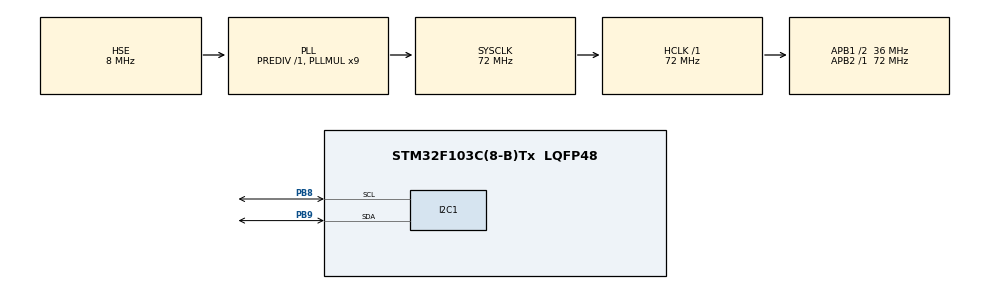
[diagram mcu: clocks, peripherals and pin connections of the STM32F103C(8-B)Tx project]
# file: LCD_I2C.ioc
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Mcu.Family=STM32F1
Mcu.Name=STM32F103C(8-B)Tx
Mcu.Package=LQFP48
NVIC.PriorityGroup=NVIC_PRIORITYGROUP_4
PA13.Mode=Serial_Wire
PA13.Signal=SYS_JTMS-SWDIO
PA14.Mode=Serial_Wire
PA14.Signal=SYS_JTCK-SWCLK
PB8.Mode=I2C
PB8.Signal=I2C1_SCL
PB9.Mode=I2C
PB9.Signal=I2C1_SDA
PD0-OSC_IN.Mode=HSE-External-Oscillator
PD0-OSC_IN.Signal=RCC_OSC_IN
PD1-OSC_OUT.Mode=HSE-External-Oscillator
PD1-OSC_OUT.Signal=RCC_OSC_OUT
ProjectManager.HeapSize=0x200
ProjectManager.StackSize=0x400
ProjectManager.TargetToolchain=STM32CubeIDE
RCC.AHBFreq_Value=72000000
RCC.APB1CLKDivider=RCC_HCLK_DIV2
RCC.APB1Freq_Value=36000000
RCC.APB1TimFreq_Value=72000000
RCC.APB2Freq_Value=72000000
RCC.APB2TimFreq_Value=72000000
RCC.HCLKFreq_Value=72000000
RCC.PLLMUL=RCC_PLL_MUL9
RCC.PLLSourceVirtual=RCC_PLLSOURCE_HSE
RCC.SYSCLKFreq_VALUE=72000000
RCC.SYSCLKSource=RCC_SYSCLKSOURCE_PLLCLK
RCC.USBFreq_Value=72000000
board=custom

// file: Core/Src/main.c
/* USER CODE BEGIN Header */
/**
  ******************************************************************************
  * @file           : main.c
  * @brief          : Main program body
  ******************************************************************************
  * @attention
  *
  * Copyright (c) 2023 STMicroelectronics.
  * All rights reserved.
  *
  * This software is licensed under terms that can be found in the LICENSE file
  * in the root directory of this software component.
  * If no LICENSE file comes with this software, it is provided AS-IS.
  *
  ******************************************************************************
  */
/* USER CODE END Header */
#include "main.h"

/* USER CODE BEGIN Includes */
#include "stdio.h"
#include "Anglas_LCD_I2C.h"
/* USER CODE END Includes */

I2C_HandleTypeDef hi2c1;

/* USER CODE BEGIN PV */
uint16_t contInt=0;
float contFloat=0.0;
char buff[16];

const uint8_t  fig_1[8] = {0x0A, 0x0A, 0x0A, 0x00, 0x11, 0x11, 0x0E, 0x00};
const uint8_t  fig_2[8] = {0x04, 0x11, 0x0E, 0x04, 0x04, 0x0A, 0x11, 0x00};
const uint8_t  fig_3[8] = {0x00, 0x0A, 0x1F, 0x1F, 0x1F, 0x0E, 0x04, 0x00};
const uint8_t  fig_4[8] = {0x0E, 0x1F, 0x1F, 0x0E, 0x0A, 0x11, 0x11, 0x00};
const uint8_t  fig_5[8] = {0x04, 0x0E, 0x1F, 0x04, 0x04, 0x04, 0x04, 0x00};
const uint8_t  fig_6[8] = {0x0E, 0x0A, 0x11, 0x11, 0x11, 0x1F, 0x1F, 0x00};
const uint8_t  fig_7[8] = {0x04, 0x0E, 0x04, 0x04, 0x15, 0x15, 0x0E, 0x00};
const uint8_t  fig_8[8] = {0x1F, 0x11, 0x0A, 0x04, 0x0A, 0x11, 0x1F, 0x00};

/* USER CODE END PV */

void SystemClock_Config(void);
static void MX_GPIO_Init(void);
static void MX_I2C1_Init(void);

int main(void)
{

  /* MCU Configuration--------------------------------------------------------*/

  /* Reset of all peripherals, Initializes the Flash interface and the Systick. */
  HAL_Init();

  /* Configure the system clock */
  SystemClock_Config();

  /* Initialize all configured peripherals */
  MX_GPIO_Init();
  MX_I2C1_Init();
  /* USER CODE BEGIN 2 */
  LCD_I2C_Init();
  LCD_I2C_CGRAM_CreateChar(1, fig_1);
  LCD_I2C_CGRAM_CreateChar(2, fig_2);
  LCD_I2C_CGRAM_CreateChar(3, fig_3);
  LCD_I2C_CGRAM_CreateChar(4, fig_4);
  LCD_I2C_CGRAM_CreateChar(5, fig_5);
  LCD_I2C_CGRAM_CreateChar(6, fig_6);
  LCD_I2C_CGRAM_CreateChar(7, fig_7);
  LCD_I2C_CGRAM_CreateChar(8, fig_8);

  LCD_I2C_WriteText(1,1," STM32F103C8T6  ");
  LCD_I2C_WriteText(2,1,"  LCD 16x2 20x4 ");
  //LCD_I2C_WriteText(3,1,"PROBANDO DISPLAY LCD");//LCD 20x4
  //LCD_I2C_WriteText(4,1,"20X4 DISPLAY LCD LCD");//LCD 20x4
  HAL_Delay(2000);

  LCD_I2C_Set_Cursor_Blink(1,16,1);//CURSOR BLINK ON
  HAL_Delay(4000);

  LCD_I2C_Set_Cursor_Blink(1,16,0);//CURSOR BLINK OFF
  LCD_I2C_ClearText();

  //Mostramos los caracteres especiales
  LCD_I2C_CGRAM_WriteChar(1,1,1);
  LCD_I2C_CGRAM_WriteChar(1,3,2);
  LCD_I2C_CGRAM_WriteChar(1,5,3);
  LCD_I2C_CGRAM_WriteChar(1,7,4);
  LCD_I2C_CGRAM_WriteChar(1,9,5);
  LCD_I2C_CGRAM_WriteChar(1,11,6);
  LCD_I2C_CGRAM_WriteChar(1,13,7);
  LCD_I2C_CGRAM_WriteChar(1,15,8);
  HAL_Delay(2000);

  LCD_I2C_WriteText(2,1,"LCD");
  HAL_Delay(2000);
  for(uint8_t i=0; i<13; i++){
	  LCD_I2C_Shift_Right();
	  HAL_Delay(350);
  }
  HAL_Delay(300);
  for(uint8_t i=0; i<13; i++){
	  LCD_I2C_Shift_Left();
	  HAL_Delay(350);
  }
  HAL_Delay(2000);

  for(uint8_t i=1; i<=13; i++){
	  LCD_I2C_WriteText(2,i,"LCD");
  	  HAL_Delay(350);
  	  LCD_I2C_WriteText(2,i,"   ");
  }
  for(uint8_t i=13; i>0; i--){
	  LCD_I2C_WriteText(2,i,"LCD");
  	  HAL_Delay(350);
  	  LCD_I2C_WriteText(2,i,"   ");
  }

  HAL_Delay(1000);
  LCD_I2C_ClearText();

  /* USER CODE END 2 */

  /* Infinite loop */
  /* USER CODE BEGIN WHILE */
  while (1)
  {
      contInt++;
      sprintf(buff,"INT  : %d",contInt);
      LCD_I2C_WriteText(1,1,buff);
      //LCD_I2C_WriteText(2,7,buff);//LCD 20x4

      contFloat+=0.1;
      sprintf(buff,"FLOAT: %4.2f",contFloat);
      LCD_I2C_WriteText(2,1,buff);
      //LCD_I2C_WriteText(3,7,buff);//LCD 20x4
    /* USER CODE END WHILE */

  }
}

void SystemClock_Config(void)
{
  RCC_OscInitTypeDef RCC_OscInitStruct = {0};
  RCC_ClkInitTypeDef RCC_ClkInitStruct = {0};

  /** Initializes the RCC Oscillators according to the specified parameters
  * in the RCC_OscInitTypeDef structure.
  */
  RCC_OscInitStruct.OscillatorType = RCC_OSCILLATORTYPE_HSE;
  RCC_OscInitStruct.HSEState = RCC_HSE_ON;
  RCC_OscInitStruct.HSEPredivValue = RCC_HSE_PREDIV_DIV1;
  RCC_OscInitStruct.HSIState = RCC_HSI_ON;
  RCC_OscInitStruct.PLL.PLLState = RCC_PLL_ON;
  RCC_OscInitStruct.PLL.PLLSource = RCC_PLLSOURCE_HSE;
  RCC_OscInitStruct.PLL.PLLMUL = RCC_PLL_MUL9;
  if (HAL_RCC_OscConfig(&RCC_OscInitStruct) != HAL_OK)
  {
    Error_Handler();
  }

  /** Initializes the CPU, AHB and APB buses clocks
  */
  RCC_ClkInitStruct.ClockType = RCC_CLOCKTYPE_HCLK|RCC_CLOCKTYPE_SYSCLK
                              |RCC_CLOCKTYPE_PCLK1|RCC_CLOCKTYPE_PCLK2;
  RCC_ClkInitStruct.SYSCLKSource = RCC_SYSCLKSOURCE_PLLCLK;
  RCC_ClkInitStruct.AHBCLKDivider = RCC_SYSCLK_DIV1;
  RCC_ClkInitStruct.APB1CLKDivider = RCC_HCLK_DIV2;
  RCC_ClkInitStruct.APB2CLKDivider = RCC_HCLK_DIV1;

  if (HAL_RCC_ClockConfig(&RCC_ClkInitStruct, FLASH_LATENCY_2) != HAL_OK)
  {
    Error_Handler();
  }
}

static void MX_I2C1_Init(void)
{

  hi2c1.Instance = I2C1;
  hi2c1.Init.ClockSpeed = 100000;
  hi2c1.Init.DutyCycle = I2C_DUTYCYCLE_2;
  hi2c1.Init.OwnAddress1 = 0;
  hi2c1.Init.AddressingMode = I2C_ADDRESSINGMODE_7BIT;
  hi2c1.Init.DualAddressMode = I2C_DUALADDRESS_DISABLE;
  hi2c1.Init.OwnAddress2 = 0;
  hi2c1.Init.GeneralCallMode = I2C_GENERALCALL_DISABLE;
  hi2c1.Init.NoStretchMode = I2C_NOSTRETCH_DISABLE;
  if (HAL_I2C_Init(&hi2c1) != HAL_OK)
  {
    Error_Handler();
  }

}

static void MX_GPIO_Init(void)
{

  /* GPIO Ports Clock Enable */
  __HAL_RCC_GPIOD_CLK_ENABLE();
  __HAL_RCC_GPIOA_CLK_ENABLE();
  __HAL_RCC_GPIOB_CLK_ENABLE();

}

void Error_Handler(void)
{
  __disable_irq();
  while (1)
  {
  }
}
